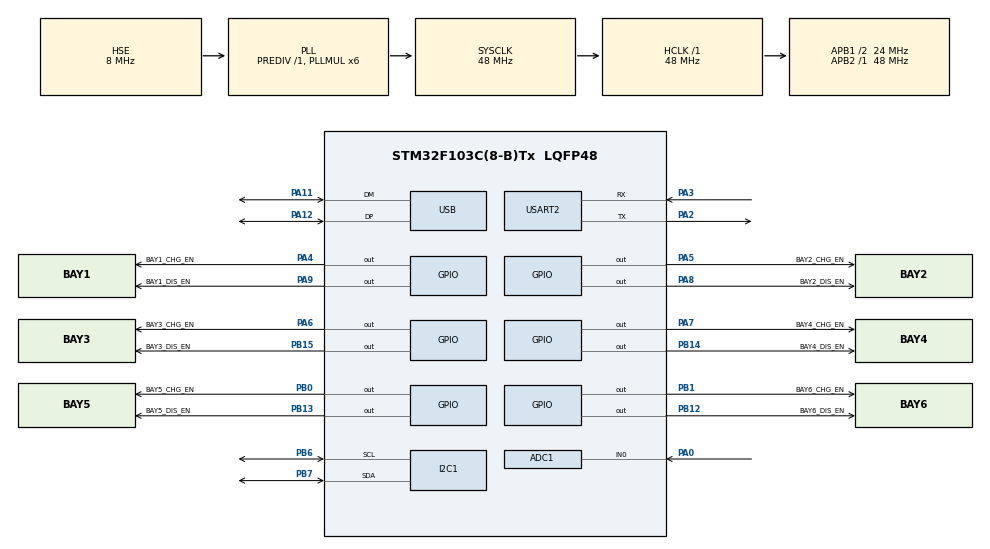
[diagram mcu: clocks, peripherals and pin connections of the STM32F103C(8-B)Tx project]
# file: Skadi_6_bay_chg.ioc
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ADC1.Channel-1\#ChannelRegularConversion=ADC_CHANNEL_0
ADC1.NbrOfConversionFlag=1
ADC1.Rank-1\#ChannelRegularConversion=1
ADC1.SamplingTime-1\#ChannelRegularConversion=ADC_SAMPLETIME_1CYCLE_5
ADC1.master=1
Mcu.Family=STM32F1
Mcu.Name=STM32F103C(8-B)Tx
Mcu.Package=LQFP48
NVIC.ADC1_2_IRQn=true\:0\:0\:false\:false\:true\:true\:true\:true
NVIC.PriorityGroup=NVIC_PRIORITYGROUP_4
NVIC.USART2_IRQn=true\:0\:0\:false\:false\:true\:true\:true\:true
NVIC.USB_LP_CAN1_RX0_IRQn=true\:0\:0\:false\:false\:true\:false\:true\:true
PA0-WKUP.Signal=ADCx_IN0
PA11.Mode=Device
PA11.Signal=USB_DM
PA12.Mode=Device
PA12.Signal=USB_DP
PA13.Mode=Trace_Asynchronous_SW
PA13.Signal=SYS_JTMS-SWDIO
PA14.Mode=Trace_Asynchronous_SW
PA14.Signal=SYS_JTCK-SWCLK
PA2.Mode=Asynchronous
PA2.Signal=USART2_TX
PA3.Mode=Asynchronous
PA3.Signal=USART2_RX
PA4.GPIO_Label=BAY1_CHG_EN
PA4.Signal=GPIO_Output
PA5.GPIO_Label=BAY2_CHG_EN
PA5.Signal=GPIO_Output
PA6.GPIO_Label=BAY3_CHG_EN
PA6.Signal=GPIO_Output
PA7.GPIO_Label=BAY4_CHG_EN
PA7.Signal=GPIO_Output
PA8.GPIO_Label=BAY2_DIS_EN
PA8.Signal=GPIO_Output
PA9.GPIO_Label=BAY1_DIS_EN
PA9.Signal=GPIO_Output
PB0.GPIO_Label=BAY5_CHG_EN
PB0.Signal=GPIO_Output
PB1.GPIO_Label=BAY6_CHG_EN
PB1.Signal=GPIO_Output
PB12.GPIO_Label=BAY6_DIS_EN
PB12.Signal=GPIO_Output
PB13.GPIO_Label=BAY5_DIS_EN
PB13.Signal=GPIO_Output
PB14.GPIO_Label=BAY4_DIS_EN
PB14.Signal=GPIO_Output
PB15.GPIO_Label=BAY3_DIS_EN
PB15.Signal=GPIO_Output
PB3.Mode=Trace_Asynchronous_SW
PB3.Signal=SYS_JTDO-TRACESWO
PB6.Mode=I2C
PB6.Signal=I2C1_SCL
PB7.Mode=I2C
PB7.Signal=I2C1_SDA
PD0-OSC_IN.Mode=HSE-External-Oscillator
PD0-OSC_IN.Signal=RCC_OSC_IN
PD1-OSC_OUT.Mode=HSE-External-Oscillator
PD1-OSC_OUT.Signal=RCC_OSC_OUT
ProjectManager.HeapSize=0x200
ProjectManager.StackSize=0x400
ProjectManager.TargetToolchain=STM32CubeIDE
RCC.ADCPresc=RCC_ADCPCLK2_DIV4
RCC.AHBFreq_Value=48000000
RCC.APB1CLKDivider=RCC_HCLK_DIV2
RCC.APB1Freq_Value=24000000
RCC.APB1TimFreq_Value=48000000
RCC.APB2Freq_Value=48000000
RCC.APB2TimFreq_Value=48000000
RCC.HCLKFreq_Value=48000000
RCC.PLLMUL=RCC_PLL_MUL6
RCC.SYSCLKFreq_VALUE=48000000
RCC.SYSCLKSource=RCC_SYSCLKSOURCE_PLLCLK
RCC.USBFreq_Value=48000000
SH.ADCx_IN0.0=ADC1_IN0,IN0
USART2.VirtualMode=VM_ASYNC
USB_DEVICE.CLASS_NAME_FS=CDC
USB_DEVICE.VirtualMode=Cdc
USB_DEVICE.VirtualModeFS=Cdc_FS
VP_USB_DEVICE_VS_USB_DEVICE_CDC_FS.Mode=CDC_FS
VP_WWDG_VS_WWDG.Mode=WWDG_Activate
board=custom

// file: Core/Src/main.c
/* USER CODE BEGIN Header */
/**
  ******************************************************************************
  * @file           : main.c
  * @brief          : Main program body
  ******************************************************************************
  * @attention
  *
  * Copyright (c) 2026 STMicroelectronics.
  * All rights reserved.
  *
  * This software is licensed under terms that can be found in the LICENSE file
  * in the root directory of this software component.
  * If no LICENSE file comes with this software, it is provided AS-IS.
  *
  ******************************************************************************
  */
/* USER CODE END Header */
#include "main.h"
#include "usb_device.h"

/* USER CODE BEGIN Includes */
#include "app.h"
#include "services_cmd.h"
/* USER CODE END Includes */

ADC_HandleTypeDef hadc1;

I2C_HandleTypeDef hi2c1;

UART_HandleTypeDef huart2;

WWDG_HandleTypeDef hwwdg;

/* USER CODE BEGIN PV */
app_t g_app;
static uint8_t ble_rx_byte;
/* USER CODE END PV */

void SystemClock_Config(void);
static void MX_GPIO_Init(void);
static void MX_ADC1_Init(void);
static void MX_I2C1_Init(void);
static void MX_USART2_UART_Init(void);
static void MX_WWDG_Init(void);

/* USER CODE BEGIN 0 */

void HAL_UART_RxCpltCallback(UART_HandleTypeDef *huart)
{
  if (huart->Instance == USART2) {
    Cmd_Ingest(&g_app, &ble_rx_byte, 1);
    (void)HAL_UART_Receive_IT(&huart2, &ble_rx_byte, 1);
  }
}

/* USER CODE END 0 */

int main(void)
{

  /* MCU Configuration--------------------------------------------------------*/

  /* Reset of all peripherals, Initializes the Flash interface and the Systick. */
  HAL_Init();

  /* Configure the system clock */
  SystemClock_Config();

  /* Initialize all configured peripherals */
  MX_GPIO_Init();
  MX_ADC1_Init();
  MX_I2C1_Init();
  MX_USART2_UART_Init();
  MX_WWDG_Init();
  MX_USB_DEVICE_Init();
  /* USER CODE BEGIN 2 */
  App_Init(&g_app);
  (void)HAL_UART_Receive_IT(&huart2, &ble_rx_byte, 1);
  /* USER CODE END 2 */

  /* Infinite loop */
  while (1)
  {

    /* 10ms scheduler tick */
    static uint32_t t0 = 0;
    uint32_t now = HAL_GetTick();

    if ((uint32_t)(now - t0) >= 10u) {
      t0 = now;

      /* Main application state machine */
      App_Tick(&g_app);

      /* Feed watchdog (WWDG) */
      (void)HAL_WWDG_Refresh(&hwwdg);
    }

  }
}

void SystemClock_Config(void)
{
  RCC_OscInitTypeDef RCC_OscInitStruct = {0};
  RCC_ClkInitTypeDef RCC_ClkInitStruct = {0};
  RCC_PeriphCLKInitTypeDef PeriphClkInit = {0};

  /** Initializes the RCC Oscillators according to the specified parameters
  * in the RCC_OscInitTypeDef structure.
  */
  RCC_OscInitStruct.OscillatorType = RCC_OSCILLATORTYPE_HSE;
  RCC_OscInitStruct.HSEState = RCC_HSE_ON;
  RCC_OscInitStruct.HSEPredivValue = RCC_HSE_PREDIV_DIV1;
  RCC_OscInitStruct.HSIState = RCC_HSI_ON;
  RCC_OscInitStruct.PLL.PLLState = RCC_PLL_ON;
  RCC_OscInitStruct.PLL.PLLSource = RCC_PLLSOURCE_HSE;
  RCC_OscInitStruct.PLL.PLLMUL = RCC_PLL_MUL6;
  if (HAL_RCC_OscConfig(&RCC_OscInitStruct) != HAL_OK)
  {
    Error_Handler();
  }

  /** Initializes the CPU, AHB and APB buses clocks
  */
  RCC_ClkInitStruct.ClockType = RCC_CLOCKTYPE_HCLK|RCC_CLOCKTYPE_SYSCLK
                              |RCC_CLOCKTYPE_PCLK1|RCC_CLOCKTYPE_PCLK2;
  RCC_ClkInitStruct.SYSCLKSource = RCC_SYSCLKSOURCE_PLLCLK;
  RCC_ClkInitStruct.AHBCLKDivider = RCC_SYSCLK_DIV1;
  RCC_ClkInitStruct.APB1CLKDivider = RCC_HCLK_DIV2;
  RCC_ClkInitStruct.APB2CLKDivider = RCC_HCLK_DIV1;

  if (HAL_RCC_ClockConfig(&RCC_ClkInitStruct, FLASH_LATENCY_1) != HAL_OK)
  {
    Error_Handler();
  }
  PeriphClkInit.PeriphClockSelection = RCC_PERIPHCLK_ADC|RCC_PERIPHCLK_USB;
  PeriphClkInit.AdcClockSelection = RCC_ADCPCLK2_DIV4;
  PeriphClkInit.UsbClockSelection = RCC_USBCLKSOURCE_PLL;
  if (HAL_RCCEx_PeriphCLKConfig(&PeriphClkInit) != HAL_OK)
  {
    Error_Handler();
  }
}

static void MX_ADC1_Init(void)
{

  ADC_ChannelConfTypeDef sConfig = {0};

  /** Common config
  */
  hadc1.Instance = ADC1;
  hadc1.Init.ScanConvMode = ADC_SCAN_DISABLE;
  hadc1.Init.ContinuousConvMode = DISABLE;
  hadc1.Init.DiscontinuousConvMode = DISABLE;
  hadc1.Init.ExternalTrigConv = ADC_SOFTWARE_START;
  hadc1.Init.DataAlign = ADC_DATAALIGN_RIGHT;
  hadc1.Init.NbrOfConversion = 1;
  if (HAL_ADC_Init(&hadc1) != HAL_OK)
  {
    Error_Handler();
  }

  /** Configure Regular Channel
  */
  sConfig.Channel = ADC_CHANNEL_0;
  sConfig.Rank = ADC_REGULAR_RANK_1;
  sConfig.SamplingTime = ADC_SAMPLETIME_1CYCLE_5;
  if (HAL_ADC_ConfigChannel(&hadc1, &sConfig) != HAL_OK)
  {
    Error_Handler();
  }

}

static void MX_I2C1_Init(void)
{

  hi2c1.Instance = I2C1;
  hi2c1.Init.ClockSpeed = 100000;
  hi2c1.Init.DutyCycle = I2C_DUTYCYCLE_2;
  hi2c1.Init.OwnAddress1 = 0;
  hi2c1.Init.AddressingMode = I2C_ADDRESSINGMODE_7BIT;
  hi2c1.Init.DualAddressMode = I2C_DUALADDRESS_DISABLE;
  hi2c1.Init.OwnAddress2 = 0;
  hi2c1.Init.GeneralCallMode = I2C_GENERALCALL_DISABLE;
  hi2c1.Init.NoStretchMode = I2C_NOSTRETCH_DISABLE;
  if (HAL_I2C_Init(&hi2c1) != HAL_OK)
  {
    Error_Handler();
  }

}

static void MX_USART2_UART_Init(void)
{

  huart2.Instance = USART2;
  huart2.Init.BaudRate = 115200;
  huart2.Init.WordLength = UART_WORDLENGTH_8B;
  huart2.Init.StopBits = UART_STOPBITS_1;
  huart2.Init.Parity = UART_PARITY_NONE;
  huart2.Init.Mode = UART_MODE_TX_RX;
  huart2.Init.HwFlowCtl = UART_HWCONTROL_NONE;
  huart2.Init.OverSampling = UART_OVERSAMPLING_16;
  if (HAL_UART_Init(&huart2) != HAL_OK)
  {
    Error_Handler();
  }

}

static void MX_WWDG_Init(void)
{

  hwwdg.Instance = WWDG;
  hwwdg.Init.Prescaler = WWDG_PRESCALER_1;
  /* Avoid early-refresh constraint: use max window/counter */
  hwwdg.Init.Window = 0x7F;
  hwwdg.Init.Counter = 0x7F;
  hwwdg.Init.EWIMode = WWDG_EWI_DISABLE;
  if (HAL_WWDG_Init(&hwwdg) != HAL_OK)
  {
    Error_Handler();
  }

}

static void MX_GPIO_Init(void)
{
  GPIO_InitTypeDef GPIO_InitStruct = {0};

  /* GPIO Ports Clock Enable */
  __HAL_RCC_GPIOD_CLK_ENABLE();
  __HAL_RCC_GPIOA_CLK_ENABLE();
  __HAL_RCC_GPIOB_CLK_ENABLE();

  /*Configure GPIO pin Output Level */
  HAL_GPIO_WritePin(GPIOA, BAY1_CHG_EN_Pin|BAY2_CHG_EN_Pin|BAY3_CHG_EN_Pin|BAY4_CHG_EN_Pin
                          |BAY2_DIS_EN_Pin|BAY1_DIS_EN_Pin, GPIO_PIN_RESET);

  /*Configure GPIO pin Output Level */
  HAL_GPIO_WritePin(GPIOB, BAY5_CHG_EN_Pin|BAY6_CHG_EN_Pin|BAY6_DIS_EN_Pin|BAY5_DIS_EN_Pin
                          |BAY4_DIS_EN_Pin|BAY3_DIS_EN_Pin, GPIO_PIN_RESET);

  /*Configure GPIO pins : BAY1_CHG_EN_Pin BAY2_CHG_EN_Pin BAY3_CHG_EN_Pin BAY4_CHG_EN_Pin
                           BAY2_DIS_EN_Pin BAY1_DIS_EN_Pin */
  GPIO_InitStruct.Pin = BAY1_CHG_EN_Pin|BAY2_CHG_EN_Pin|BAY3_CHG_EN_Pin|BAY4_CHG_EN_Pin
                          |BAY2_DIS_EN_Pin|BAY1_DIS_EN_Pin;
  GPIO_InitStruct.Mode = GPIO_MODE_OUTPUT_PP;
  GPIO_InitStruct.Pull = GPIO_NOPULL;
  GPIO_InitStruct.Speed = GPIO_SPEED_FREQ_LOW;
  HAL_GPIO_Init(GPIOA, &GPIO_InitStruct);

  /*Configure GPIO pins : BAY5_CHG_EN_Pin BAY6_CHG_EN_Pin BAY6_DIS_EN_Pin BAY5_DIS_EN_Pin
                           BAY4_DIS_EN_Pin BAY3_DIS_EN_Pin */
  GPIO_InitStruct.Pin = BAY5_CHG_EN_Pin|BAY6_CHG_EN_Pin|BAY6_DIS_EN_Pin|BAY5_DIS_EN_Pin
                          |BAY4_DIS_EN_Pin|BAY3_DIS_EN_Pin;
  GPIO_InitStruct.Mode = GPIO_MODE_OUTPUT_PP;
  GPIO_InitStruct.Pull = GPIO_NOPULL;
  GPIO_InitStruct.Speed = GPIO_SPEED_FREQ_LOW;
  HAL_GPIO_Init(GPIOB, &GPIO_InitStruct);

}

void Error_Handler(void)
{
  __disable_irq();
  while (1)
  {
  }
}
